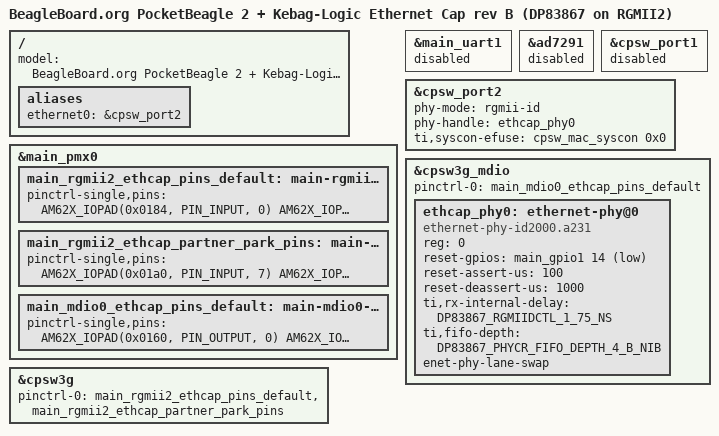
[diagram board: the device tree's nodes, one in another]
// SPDX-License-Identifier: GPL-2.0-only OR MIT
/*
 * Kebag-Logic PocketBeagle 2 Ethernet Cap, rev B: a DP83867IR gigabit PHY on
 * CPSW3G port 2 (RGMII2), for the BeagleBoard.org PocketBeagle 2 (AM6254).
 *
 *   https://github.com/kebag-logic/pocketbeagle2_ethernet_cap
 *   (rev B = the revb-respin merge; documentation/handover_revb_respin.md)
 *
 * SPDX-FileCopyrightText: Copyright (c) 2026 Kebag-Logic
 *
 * Header pins the cap uses
 * ------------------------
 * Read from the cap's PCB pad nets (U1 = the PocketBeagle 2 footprint, pad k =
 * P1.k, pad 36+k = P2.k) and cross-checked against the PocketBeagle 2 SRM
 * §4.2 "Cape Header Connectors":
 *
 *   P1.02  AA19  pad 0x164  mux 0  RGMII2_TX_CTL   out   (+ E18 MCASP0_AXR0)
 *   P1.04  Y18   pad 0x16c  mux 0  RGMII2_TD0      out   (+ D20 MCASP0_AFSX)
 *   P2.31  AA18  pad 0x170  mux 0  RGMII2_TD1      out   (+ A13 SPI0_CS0)
 *   P2.10  AD21  pad 0x174  mux 0  RGMII2_TD2      out
 *   P2.19  AC20  pad 0x178  mux 0  RGMII2_TD3      out
 *   P1.35  AE21  pad 0x168  mux 0  RGMII2_TXC      out
 *   P1.19  AD22  pad 0x17c  mux 0  RGMII2_RX_CTL   in    (AIN0)
 *   P1.27  AE23  pad 0x184  mux 0  RGMII2_RD0      in    (AIN4)
 *   P1.25  AB20  pad 0x188  mux 0  RGMII2_RD1      in    (AIN3)
 *   P1.23  AC21  pad 0x18c  mux 0  RGMII2_RD2      in    (AIN2)
 *   P1.21  AE22  pad 0x190  mux 0  RGMII2_RD3      in    (AIN1)
 *   P1.34  AD23  pad 0x180  mux 0  RGMII2_RXC      in
 *   P2.01  AD24  pad 0x160  mux 0  MDIO0_MDC       out   (+ B20 MCASP0_ACLKX)
 *   P2.03  AB22  pad 0x15c  mux 0  MDIO0_MDIO      i/o   (+ B18 MCASP0_AXR1)
 *   P1.08  A20   pad 0x1b0  mux 7  GPIO1_14        out   PHY RESET_N
 *   P1.06  E19   pad 0x1ac  mux 7  GPIO1_13        in    PHY INT/PWDN_N, 2k2 pull-up
 *                                                        (+ AD18 RGMII1_TD3)
 *   P1.14 / P2.23  3V3 feeds the cap (VDDIO, oscillator, both LDOs)
 *
 * RGMII2 on PocketBeagle 2 is in the 3.3 V VDDSHV2 domain, matching the PHY's
 * 3.3 V VDDIO.  This is the pin set the TDM8 trees use for McASP0 (P1.02,
 * P1.04, P2.01, P2.03), so with the cap fitted the TDM8 link cannot run: boot
 * this tree, not a TDM8 one.
 *
 * Two balls per header pin
 * ------------------------
 * Six of those header pins also carry a second SoC ball (marked "+" above).
 * Each partner is parked at mux 7, PIN_INPUT: a GPIO nobody claims stays an
 * input and PIN_INPUT has no pull, so the partner neither drives nor loads the
 * RGMII/MDIO line (rev B handover §2.1: "keep the second balls as inputs with
 * no pull").  The receivers stay on, so gpioget still reads the line back.
 *
 * The PHY interrupt is NOT wired up.  INT/PWDN_N is an open-drain level
 * interrupt and the DaVinci GPIO controller only takes edge triggers, so the
 * PHY is polled (link changes show up within a second).  E19 is parked as a
 * plain input so the line can still be read with gpioget.
 *
 * P1.06/P1.08 are MAIN_UART1 RXD/TXD in the stock tree (status "reserved",
 * bootph-pre-ram).  U-Boot still muxes them as UART1 before Linux; Linux then
 * takes A20 as the PHY reset GPIO, and &main_uart1 is disabled here so nothing
 * in Linux muxes them back.
 *
 * The MSPM0 ADC inputs
 * --------------------
 * P1.19/21/23/25/27 are the PocketBeagle 2's AIN0..AIN4, which the on-board
 * MSPM0 samples and presents as an emulated AD7291 on main_i2c0.  With the cap
 * fitted those pins are the RGMII receive bus, so the ADC readings mean
 * nothing.  &ad7291 is disabled so Linux never asks the MSPM0 to convert on a
 * live 125 MHz data line.
 *
 * The PHY (DP83867IRPAP, rev B straps)
 * ------------------------------------
 *   RX_D0, RX_D2, RX_D4  no strap    mode 1  PHY address 0
 *   RX_CTRL     5k76 up / 2k49 down  mode 3  autoneg enabled (the mode-1 RX_CTRL
 *                                            of rev A is fixed, so the
 *                                            ti,dp83867-rxctrl-strap-quirk
 *                                            is NOT needed on rev B)
 *   RX_D6       no strap             mode 1  RGMII enabled, auto-MDIX on
 *   RX_D7       2k49 up              mode 4  speed optimisation on, CLK_OUT off
 *   LED_0       5k76 up / 2k49 down  mode 3  RJ45 port mirroring on, LED active high
 *   LED_1/2     no strap             mode 1  LEDs active high (BSS138 drivers)
 *
 * Mirroring is strap-enabled.  enet-phy-lane-swap below writes the same bit
 * again, so a marginal strap read at reset cannot leave the A<->D / B<->C
 * swapped MDI routing of rev B without the swap that it needs.
 *
 * RGMII delays
 * ------------
 * The PCB adds no delay.  "rgmii-id" is the honest description; am65-cpsw
 * then enables the AM62x MAC's internal TX delay and hands the PHY
 * "rgmii-rxid", so the DP83867 adds only the RX delay.  The rev B routing
 * makes RX_CLK 14.1 mm (~95 ps) longer than RD0..3, and the handover's
 * starting value is 1.75 ns, which with the routing comes to ~1.85 ns of RX
 * skew.  Tune in 0.25 ns steps (DP83867_RGMIIDCTL_*) if the 1000 Mb/s link
 * shows errors.
 */

#include <dt-bindings/net/ti-dp83867.h>
#include "k3-am62-pocketbeagle2.dts"

/ {
	model = "BeagleBoard.org PocketBeagle 2 + Kebag-Logic Ethernet Cap rev B (DP83867 on RGMII2)";

	aliases {
		ethernet0 = &cpsw_port2;
	};
};

&main_pmx0 {
	main_rgmii2_ethcap_pins_default: main-rgmii2-ethcap-default-pins {
		pinctrl-single,pins = <
			AM62X_IOPAD(0x0184, PIN_INPUT, 0)  /* (AE23) RGMII2_RD0     P1.27 */
			AM62X_IOPAD(0x0188, PIN_INPUT, 0)  /* (AB20) RGMII2_RD1     P1.25 */
			AM62X_IOPAD(0x018c, PIN_INPUT, 0)  /* (AC21) RGMII2_RD2     P1.23 */
			AM62X_IOPAD(0x0190, PIN_INPUT, 0)  /* (AE22) RGMII2_RD3     P1.21 */
			AM62X_IOPAD(0x0180, PIN_INPUT, 0)  /* (AD23) RGMII2_RXC     P1.34 */
			AM62X_IOPAD(0x017c, PIN_INPUT, 0)  /* (AD22) RGMII2_RX_CTL  P1.19 */
			AM62X_IOPAD(0x016c, PIN_OUTPUT, 0) /* (Y18)  RGMII2_TD0     P1.04 */
			AM62X_IOPAD(0x0170, PIN_OUTPUT, 0) /* (AA18) RGMII2_TD1     P2.31 */
			AM62X_IOPAD(0x0174, PIN_OUTPUT, 0) /* (AD21) RGMII2_TD2     P2.10 */
			AM62X_IOPAD(0x0178, PIN_OUTPUT, 0) /* (AC20) RGMII2_TD3     P2.19 */
			AM62X_IOPAD(0x0168, PIN_OUTPUT, 0) /* (AE21) RGMII2_TXC     P1.35 */
			AM62X_IOPAD(0x0164, PIN_OUTPUT, 0) /* (AA19) RGMII2_TX_CTL  P1.02 */
		>;
	};

	/* the second SoC ball on the cap's shared header pins - see the header */
	main_rgmii2_ethcap_partner_park_pins: main-rgmii2-ethcap-partner-park-pins {
		pinctrl-single,pins = <
			AM62X_IOPAD(0x01a0, PIN_INPUT, 7) /* (E18)  GPIO1_10  P1.02, was MCASP0_AXR0 */
			AM62X_IOPAD(0x01a8, PIN_INPUT, 7) /* (D20)  GPIO1_12  P1.04, was MCASP0_AFSX */
			AM62X_IOPAD(0x01b4, PIN_INPUT, 7) /* (A13)  GPIO1_15  P2.31, was SPI0_CS0 */
			AM62X_IOPAD(0x01a4, PIN_INPUT, 7) /* (B20)  GPIO1_11  P2.01, was MCASP0_ACLKX */
			AM62X_IOPAD(0x019c, PIN_INPUT, 7) /* (B18)  GPIO1_9   P2.03, was MCASP0_AXR1 */
			AM62X_IOPAD(0x0140, PIN_INPUT, 7) /* (AD18) GPIO0_78  P1.06, was RGMII1_TD3 */
			AM62X_IOPAD(0x01ac, PIN_INPUT, 7) /* (E19)  GPIO1_13  P1.06, PHY INT/PWDN_N (polled) */
		>;
	};

	main_mdio0_ethcap_pins_default: main-mdio0-ethcap-default-pins {
		pinctrl-single,pins = <
			AM62X_IOPAD(0x0160, PIN_OUTPUT, 0) /* (AD24) MDIO0_MDC   P2.01 */
			AM62X_IOPAD(0x015c, PIN_INPUT, 0)  /* (AB22) MDIO0_MDIO  P2.03 */
			AM62X_IOPAD(0x01b0, PIN_OUTPUT, 7) /* (A20)  GPIO1_14    P1.08, PHY RESET_N */
		>;
	};
};

/* P1.06 / P1.08 are MAIN_UART1 RXD/TXD in the stock tree */
&main_uart1 {
	status = "disabled";
};

/* AIN0..AIN4 are the RGMII receive bus with the cap fitted */
&ad7291 {
	status = "disabled";
};

&cpsw3g {
	pinctrl-names = "default";
	pinctrl-0 = <&main_rgmii2_ethcap_pins_default
		     &main_rgmii2_ethcap_partner_park_pins>;
	status = "okay";
};

/* RGMII1 has no header pins on PocketBeagle 2 */
&cpsw_port1 {
	status = "disabled";
};

&cpsw_port2 {
	phy-mode = "rgmii-id";
	phy-handle = <&ethcap_phy0>;
	/*
	 * k3-am62-main.dtsi gives only port 1 the eFuse MAC.  Port 1 is off,
	 * so port 2 takes that one address: a stable, board-unique MAC instead
	 * of a random one on every boot.
	 */
	ti,syscon-efuse = <&cpsw_mac_syscon 0x0>;
};

&cpsw3g_mdio {
	pinctrl-names = "default";
	pinctrl-0 = <&main_mdio0_ethcap_pins_default>;
	status = "okay";

	ethcap_phy0: ethernet-phy@0 {
		/*
		 * The ID lets the PHY be created without reading it over MDIO
		 * while its reset is still asserted.
		 */
		compatible = "ethernet-phy-id2000.a231", "ethernet-phy-ieee802.3-c22";
		reg = <0>;

		/*
		 * RESET_N pulse >= 1 us, then 195 us before the first MDIO
		 * access (SNLS484J, reset timing).  The straps are latched on
		 * this edge, after the RGMII pads above are already inputs.
		 */
		reset-gpios = <&main_gpio1 14 GPIO_ACTIVE_LOW>;
		reset-assert-us = <100>;
		reset-deassert-us = <1000>;

		ti,rx-internal-delay = <DP83867_RGMIIDCTL_1_75_NS>;
		ti,fifo-depth = <DP83867_PHYCR_FIFO_DEPTH_4_B_NIB>;
		enet-phy-lane-swap;
	};
};
